CM_ "AUTOGENERATED FILE, DO NOT EDIT";

CM_ "chrysler_jeep_commander.dbc starts here";
"CM_ "IMPORT _stellantis_common.dbc";"

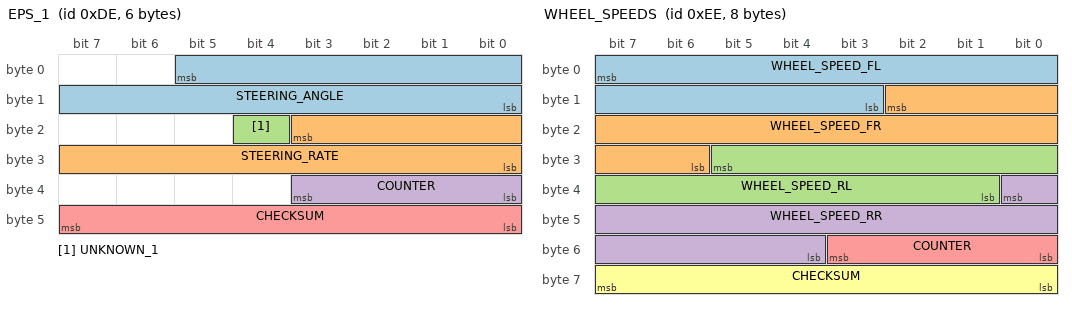
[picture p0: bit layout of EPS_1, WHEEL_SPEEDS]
BO_ 222 EPS_1: 6 EPS
 SG_ STEERING_ANGLE : 5|14@0+ (0.1,-716.8) [0|16383] "deg" XXX
 SG_ STEERING_RATE : 19|12@0+ (0.5,-1000) [0|4095] "deg/s" XXX
 SG_ UNKNOWN_1 : 20|1@0+ (1,0) [0|1] "" XXX
 SG_ COUNTER : 35|4@0+ (1,0) [0|15] "" XXX
 SG_ CHECKSUM : 47|8@0+ (1,0) [0|255] "" XXX

BO_ 238 WHEEL_SPEEDS: 8 XXX
 SG_ WHEEL_SPEED_FL : 7|13@0+ (0.017,0) [0|8191] "m/s" XXX
 SG_ WHEEL_SPEED_FR : 10|13@0+ (0.017,0) [0|8191] "m/s" XXX
 SG_ WHEEL_SPEED_RL : 29|13@0+ (0.017,0) [0|8191] "m/s" XXX
 SG_ WHEEL_SPEED_RR : 32|13@0+ (0.017,0) [0|8191] "m/s" XXX
 SG_ COUNTER : 51|4@0+ (1,0) [0|15] "" XXX
 SG_ CHECKSUM : 63|8@0+ (1,0) [0|255] "" XXX

BO_ 250 BRAKE_PRESSED_4: 8 XXX
 SG_ BRAKE_PRESSED_4 : 2|1@0+ (1,0) [0|1] "" XXX

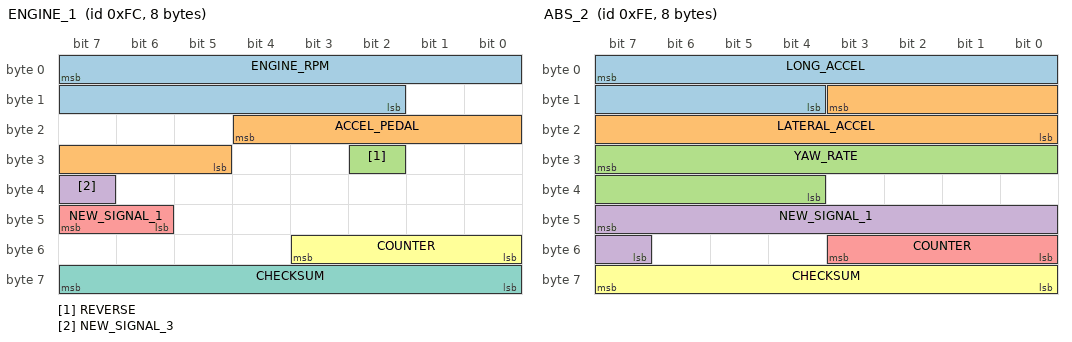
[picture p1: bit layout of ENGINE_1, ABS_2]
BO_ 252 ENGINE_1: 8 ENGINE
 SG_ ENGINE_RPM : 7|14@0+ (1,0) [0|255] "rev/min" XXX
 SG_ ACCEL_PEDAL : 20|8@0+ (0.4,0) [0|255] "percent" XXX
 SG_ REVERSE : 26|1@0+ (1,0) [0|1] "" XXX
 SG_ NEW_SIGNAL_3 : 39|1@0+ (1,0) [0|1] "" XXX
 SG_ NEW_SIGNAL_1 : 46|2@1+ (1,0) [0|3] "" XXX
 SG_ COUNTER : 51|4@0+ (1,0) [0|15] "" XXX
 SG_ CHECKSUM : 63|8@0+ (1,0) [0|255] "" XXX

BO_ 254 ABS_2: 8 ABS
 SG_ LONG_ACCEL : 7|12@0+ (0.01,-20.48) [0|4095] "m/s2" XXX
 SG_ LATERAL_ACCEL : 11|12@0+ (0.01,-20.48) [0|4095] "m/s2" XXX
 SG_ YAW_RATE : 31|12@0+ (-0.0014,2.86) [0|4095] "rad/s" XXX
 SG_ NEW_SIGNAL_1 : 47|9@0+ (1,0) [0|511] "" XXX
 SG_ COUNTER : 51|4@0+ (1,0) [0|15] "" XXX
 SG_ CHECKSUM : 63|8@0+ (1,0) [0|255] "" XXX

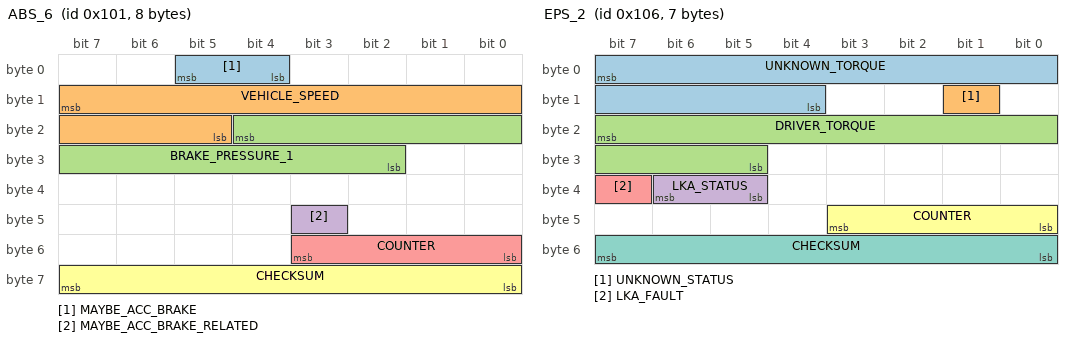
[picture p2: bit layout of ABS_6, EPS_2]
BO_ 257 ABS_6: 8 ABS
 SG_ MAYBE_ACC_BRAKE : 5|2@0+ (1,0) [0|1] "" XXX
 SG_ VEHICLE_SPEED : 15|11@0+ (0.017,0) [0|2047] "" XXX
 SG_ BRAKE_PRESSURE_1 : 20|11@0+ (1,0) [0|2047] "" XXX
 SG_ MAYBE_ACC_BRAKE_RELATED : 43|1@0+ (1,0) [0|4095] "" XXX
 SG_ COUNTER : 51|4@0+ (1,0) [0|15] "" XXX
 SG_ CHECKSUM : 63|8@0+ (1,0) [0|255] "" XXX

BO_ 262 EPS_2: 7 EPS
 SG_ UNKNOWN_TORQUE : 7|12@0+ (1,-2000) [0|4095] "" XXX
 SG_ UNKNOWN_STATUS : 9|1@0+ (1,0) [0|1] "" XXX
 SG_ DRIVER_TORQUE : 23|11@0+ (1,-1024) [0|2047] "" XXX
 SG_ LKA_STATUS : 38|2@0+ (1,0) [0|3] "" XXX
 SG_ LKA_FAULT : 39|1@0+ (1,0) [0|1] "" XXX
 SG_ COUNTER : 43|4@0+ (1,0) [0|15] "" XXX
 SG_ CHECKSUM : 55|8@0+ (1,0) [0|255] "" XXX

BO_ 278 NEW_MSG_116: 8 XXX

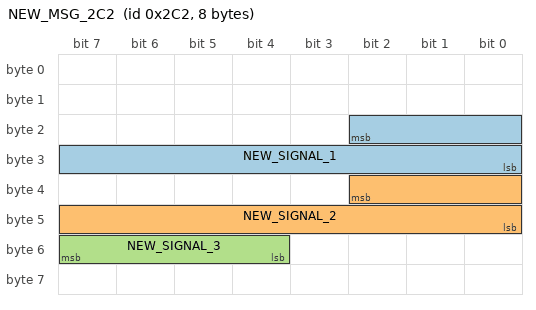
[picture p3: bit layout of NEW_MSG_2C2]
BO_ 706 NEW_MSG_2C2: 8 XXX
 SG_ NEW_SIGNAL_1 : 18|11@0+ (1,0) [0|127] "" XXX
 SG_ NEW_SIGNAL_2 : 34|11@0+ (1,0) [0|2047] "" XXX
 SG_ NEW_SIGNAL_3 : 55|4@0+ (1,0) [0|15] "" XXX

BO_ 1854 BCM_1: 4 BCM
 SG_ RIGHT_TURN_STALK : 16|1@0+ (1,0) [0|1] "" XXX
 SG_ LEFT_TURN_STALK : 17|1@0+ (1,0) [0|1] "" XXX
